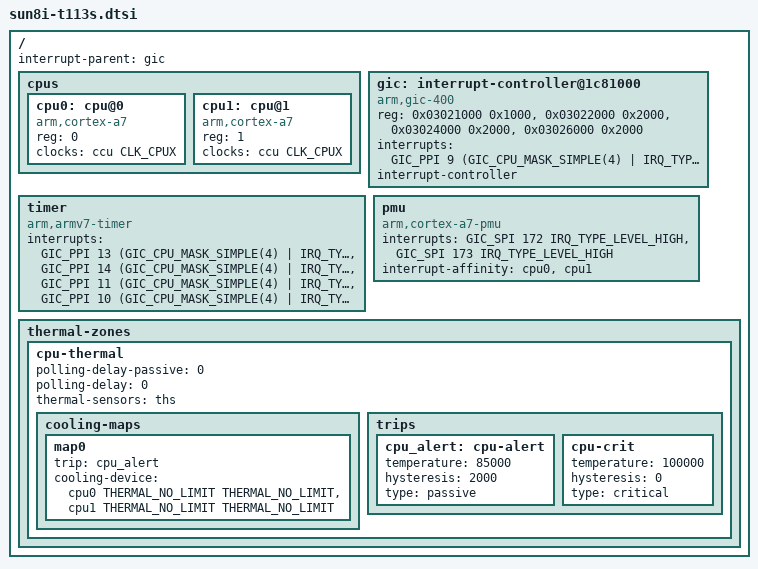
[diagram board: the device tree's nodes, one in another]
// SPDX-License-Identifier: (GPL-2.0+ OR MIT)
// Copyright (C) 2022 Arm Ltd.

#define SOC_PERIPHERAL_IRQ(nr) GIC_SPI nr

#include <dt-bindings/interrupt-controller/arm-gic.h>
#include <dt-bindings/thermal/thermal.h>
#include <riscv/allwinner/sunxi-d1s-t113.dtsi>
#include <riscv/allwinner/sunxi-d1-t113.dtsi>

/ {
	interrupt-parent = <&gic>;

	cpus {
		#address-cells = <1>;
		#size-cells = <0>;

		cpu0: cpu@0 {
			compatible = "arm,cortex-a7";
			device_type = "cpu";
			reg = <0>;
			clocks = <&ccu CLK_CPUX>;
			clock-names = "cpu";
			#cooling-cells = <2>;
		};

		cpu1: cpu@1 {
			compatible = "arm,cortex-a7";
			device_type = "cpu";
			reg = <1>;
			clocks = <&ccu CLK_CPUX>;
			clock-names = "cpu";
			#cooling-cells = <2>;
		};
	};

	gic: interrupt-controller@1c81000 {
		compatible = "arm,gic-400";
		reg = <0x03021000 0x1000>,
		      <0x03022000 0x2000>,
		      <0x03024000 0x2000>,
		      <0x03026000 0x2000>;
		interrupts = <GIC_PPI 9 (GIC_CPU_MASK_SIMPLE(4) | IRQ_TYPE_LEVEL_HIGH)>;
		interrupt-controller;
		#interrupt-cells = <3>;
	};

	timer {
		compatible = "arm,armv7-timer";
		interrupts = <GIC_PPI 13 (GIC_CPU_MASK_SIMPLE(4) | IRQ_TYPE_LEVEL_LOW)>,
			     <GIC_PPI 14 (GIC_CPU_MASK_SIMPLE(4) | IRQ_TYPE_LEVEL_LOW)>,
			     <GIC_PPI 11 (GIC_CPU_MASK_SIMPLE(4) | IRQ_TYPE_LEVEL_LOW)>,
			     <GIC_PPI 10 (GIC_CPU_MASK_SIMPLE(4) | IRQ_TYPE_LEVEL_LOW)>;
	};

	pmu {
		compatible = "arm,cortex-a7-pmu";
		interrupts = <GIC_SPI 172 IRQ_TYPE_LEVEL_HIGH>,
			     <GIC_SPI 173 IRQ_TYPE_LEVEL_HIGH>;
		interrupt-affinity = <&cpu0>, <&cpu1>;
	};

	thermal-zones {
		cpu-thermal {
			polling-delay-passive = <0>;
			polling-delay = <0>;
			thermal-sensors = <&ths>;

			cooling-maps {
				map0 {
					trip = <&cpu_alert>;
					cooling-device = <&cpu0 THERMAL_NO_LIMIT THERMAL_NO_LIMIT>,
							 <&cpu1 THERMAL_NO_LIMIT THERMAL_NO_LIMIT>;
				};
			};

			trips {
				cpu_alert: cpu-alert {
					temperature = <85000>;
					hysteresis = <2000>;
					type = "passive";
				};

				cpu-crit {
					temperature = <100000>;
					hysteresis = <0>;
					type = "critical";
				};
			};
		};
	};
};
